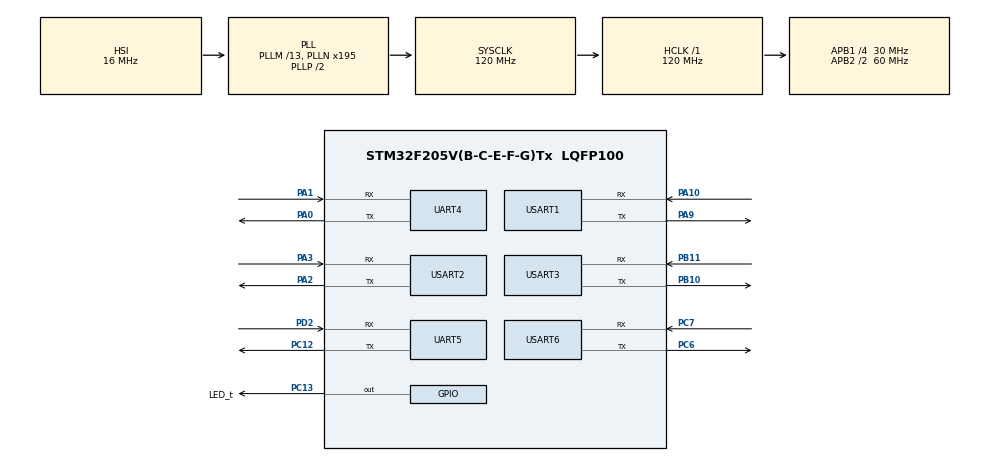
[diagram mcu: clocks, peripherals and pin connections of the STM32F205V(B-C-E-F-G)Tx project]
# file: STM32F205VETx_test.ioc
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FREERTOS.Tasks01=defaultTask,0,128,StartDefaultTask,Default,NULL,Dynamic,NULL,NULL;UartTask,-3,128,StartUartTask,Default,NULL,Static,UartTaskBuffer,UartTaskControlBlock
Mcu.Family=STM32F2
Mcu.Name=STM32F205V(B-C-E-F-G)Tx
Mcu.Package=LQFP100
NVIC.PriorityGroup=NVIC_PRIORITYGROUP_4
NVIC.TIM1_UP_TIM10_IRQn=true\:0\:0\:false\:false\:true\:false\:false\:true
NVIC.TimeBase=TIM1_UP_TIM10_IRQn
NVIC.TimeBaseIP=TIM1
PA0-WKUP.Mode=Asynchronous
PA0-WKUP.Signal=UART4_TX
PA1.Mode=Asynchronous
PA1.Signal=UART4_RX
PA10.Mode=Asynchronous
PA10.Signal=USART1_RX
PA2.Mode=Asynchronous
PA2.Signal=USART2_TX
PA3.Mode=Asynchronous
PA3.Signal=USART2_RX
PA9.Mode=Asynchronous
PA9.Signal=USART1_TX
PB10.Mode=Asynchronous
PB10.Signal=USART3_TX
PB11.Mode=Asynchronous
PB11.Signal=USART3_RX
PC12.Mode=Asynchronous
PC12.Signal=UART5_TX
PC13.GPIO_Label=LED_t
PC13.GPIO_ModeDefaultOutputPP=GPIO_MODE_OUTPUT_PP
PC13.GPIO_PuPd=GPIO_PULLUP
PC13.Signal=GPIO_Output
PC6.Mode=Asynchronous
PC6.Signal=USART6_TX
PC7.Mode=Asynchronous
PC7.Signal=USART6_RX
PD2.Mode=Asynchronous
PD2.Signal=UART5_RX
PH0-OSC_IN.Mode=HSE-External-Oscillator
PH0-OSC_IN.Signal=RCC_OSC_IN
PH1-OSC_OUT.Mode=HSE-External-Oscillator
PH1-OSC_OUT.Signal=RCC_OSC_OUT
ProjectManager.HeapSize=0x200
ProjectManager.StackSize=0x400
ProjectManager.TargetToolchain=MDK-ARM V5.27
RCC.48MHZClocksFreq_Value=60000000
RCC.AHBFreq_Value=120000000
RCC.APB1CLKDivider=RCC_HCLK_DIV4
RCC.APB1Freq_Value=30000000
RCC.APB1TimFreq_Value=60000000
RCC.APB2CLKDivider=RCC_HCLK_DIV2
RCC.APB2Freq_Value=60000000
RCC.APB2TimFreq_Value=120000000
RCC.CortexFreq_Value=120000000
RCC.HCLKFreq_Value=120000000
RCC.HSE_VALUE=8000000
RCC.HSI_VALUE=16000000
RCC.LSE_VALUE=32768
RCC.PLLM=13
RCC.PLLN=195
RCC.SYSCLKFreq_VALUE=120000000
RCC.SYSCLKSource=RCC_SYSCLKSOURCE_PLLCLK
RCC.VCOOutputFreq_Value=240000000
UART4.VirtualMode=Asynchronous
UART5.VirtualMode=Asynchronous
USART1.VirtualMode=VM_ASYNC
USART2.VirtualMode=VM_ASYNC
USART3.VirtualMode=VM_ASYNC
USART6.VirtualMode=VM_ASYNC
VP_FREERTOS_VS_CMSIS_V1.Mode=CMSIS_V1
VP_SYS_VS_tim1.Mode=TIM1
board=custom

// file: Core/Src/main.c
/* USER CODE BEGIN Header */
/**
  ******************************************************************************
  * @file           : main.c
  * @brief          : Main program body
  ******************************************************************************
  * @attention
  *
  * <h2><center>&copy; Copyright (c) 2022 STMicroelectronics.
  * All rights reserved.</center></h2>
  *
  * This software component is licensed by ST under Ultimate Liberty license
  * SLA0044, the "License"; You may not use this file except in compliance with
  * the License. You may obtain a copy of the License at:
  *                             www.st.com/SLA0044
  *
  ******************************************************************************
  */
/* USER CODE END Header */
#include "main.h"
#include "cmsis_os.h"
#include "usart.h"
#include "gpio.h"

void SystemClock_Config(void);
void MX_FREERTOS_Init(void);

/* USER CODE BEGIN 0 */
void vTaskCode( void * pvParameters )
 {
	 for( ;; )
	 {
		 // Task code goes here.
	 }
 }
/* USER CODE END 0 */

int main(void)
{

  /* MCU Configuration--------------------------------------------------------*/

  /* Reset of all peripherals, Initializes the Flash interface and the Systick. */
  HAL_Init();

  /* Configure the system clock */
  SystemClock_Config();

  /* Initialize all configured peripherals */
  MX_GPIO_Init();
  MX_USART1_UART_Init();
  MX_UART4_Init();
  MX_UART5_Init();
  MX_USART2_UART_Init();
  MX_USART3_UART_Init();
  MX_USART6_UART_Init();

  /* Call init function for freertos objects (in freertos.c) */
  MX_FREERTOS_Init();
  /* Start scheduler */
  osKernelStart();

  /* We should never get here as control is now taken by the scheduler */
  /* Infinite loop */
    while (1)
    {

    }
}

void SystemClock_Config(void)
{
  RCC_OscInitTypeDef RCC_OscInitStruct = {0};
  RCC_ClkInitTypeDef RCC_ClkInitStruct = {0};

  /** Initializes the RCC Oscillators according to the specified parameters
  * in the RCC_OscInitTypeDef structure.
  */
  RCC_OscInitStruct.OscillatorType = RCC_OSCILLATORTYPE_HSI;
  RCC_OscInitStruct.HSIState = RCC_HSI_ON;
  RCC_OscInitStruct.HSICalibrationValue = RCC_HSICALIBRATION_DEFAULT;
  RCC_OscInitStruct.PLL.PLLState = RCC_PLL_ON;
  RCC_OscInitStruct.PLL.PLLSource = RCC_PLLSOURCE_HSI;
  RCC_OscInitStruct.PLL.PLLM = 13;
  RCC_OscInitStruct.PLL.PLLN = 195;
  RCC_OscInitStruct.PLL.PLLP = RCC_PLLP_DIV2;
  RCC_OscInitStruct.PLL.PLLQ = 4;
  if (HAL_RCC_OscConfig(&RCC_OscInitStruct) != HAL_OK)
  {
    Error_Handler();
  }
  /** Initializes the CPU, AHB and APB buses clocks
  */
  RCC_ClkInitStruct.ClockType = RCC_CLOCKTYPE_HCLK|RCC_CLOCKTYPE_SYSCLK
                              |RCC_CLOCKTYPE_PCLK1|RCC_CLOCKTYPE_PCLK2;
  RCC_ClkInitStruct.SYSCLKSource = RCC_SYSCLKSOURCE_PLLCLK;
  RCC_ClkInitStruct.AHBCLKDivider = RCC_SYSCLK_DIV1;
  RCC_ClkInitStruct.APB1CLKDivider = RCC_HCLK_DIV4;
  RCC_ClkInitStruct.APB2CLKDivider = RCC_HCLK_DIV2;

  if (HAL_RCC_ClockConfig(&RCC_ClkInitStruct, FLASH_LATENCY_3) != HAL_OK)
  {
    Error_Handler();
  }
}

 /**
  * @brief  Period elapsed callback in non blocking mode
  * @note   This function is called  when TIM1 interrupt took place, inside
  * HAL_TIM_IRQHandler(). It makes a direct call to HAL_IncTick() to increment
  * a global variable "uwTick" used as application time base.
  * @param  htim : TIM handle
  * @retval None
  */
void HAL_TIM_PeriodElapsedCallback(TIM_HandleTypeDef *htim)
{
  if (htim->Instance == TIM1) {
    HAL_IncTick();
  }
}

void Error_Handler(void)
{
    __disable_irq();
    while (1)
    {
    }
}

/************************ (C) COPYRIGHT STMicroelectronics *****END OF FILE****/

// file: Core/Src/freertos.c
/* USER CODE BEGIN Header */
/**
  ******************************************************************************
  * File Name          : freertos.c
  * Description        : Code for freertos applications
  ******************************************************************************
  * @attention
  *
  * <h2><center>&copy; Copyright (c) 2022 STMicroelectronics.
  * All rights reserved.</center></h2>
  *
  * This software component is licensed by ST under Ultimate Liberty license
  * SLA0044, the "License"; You may not use this file except in compliance with
  * the License. You may obtain a copy of the License at:
  *                             www.st.com/SLA0044
  *
  ******************************************************************************
  */
/* USER CODE END Header */

#include "FreeRTOS.h"
#include "task.h"
#include "main.h"
#include "cmsis_os.h"

/* USER CODE BEGIN Includes */
#include "SDCard.h"
/* USER CODE END Includes */

osThreadId defaultTaskHandle;
osThreadId UartTaskHandle;
uint32_t UartTaskBuffer[ 128 ];
osStaticThreadDef_t UartTaskControlBlock;

void StartDefaultTask(void const * argument);
void StartUartTask(void const * argument);

void MX_FREERTOS_Init(void); /* (MISRA C 2004 rule 8.1) */

/* GetIdleTaskMemory prototype (linked to static allocation support) */
void vApplicationGetIdleTaskMemory( StaticTask_t **ppxIdleTaskTCBBuffer, StackType_t **ppxIdleTaskStackBuffer, uint32_t *pulIdleTaskStackSize );

/* USER CODE BEGIN GET_IDLE_TASK_MEMORY */
static StaticTask_t xIdleTaskTCBBuffer;
static StackType_t xIdleStack[configMINIMAL_STACK_SIZE];

void vApplicationGetIdleTaskMemory( StaticTask_t **ppxIdleTaskTCBBuffer, StackType_t **ppxIdleTaskStackBuffer, uint32_t *pulIdleTaskStackSize )
{
    *ppxIdleTaskTCBBuffer = &xIdleTaskTCBBuffer;
    *ppxIdleTaskStackBuffer = &xIdleStack[0];
    *pulIdleTaskStackSize = configMINIMAL_STACK_SIZE;
    /* place for user code */
}
/* USER CODE END GET_IDLE_TASK_MEMORY */

void MX_FREERTOS_Init(void) {

  /* Create the thread(s) */
  /* definition and creation of defaultTask */
  osThreadDef(defaultTask, StartDefaultTask, osPriorityNormal, 0, 128);
  defaultTaskHandle = osThreadCreate(osThread(defaultTask), NULL);

  /* definition and creation of UartTask */
  osThreadStaticDef(UartTask, StartUartTask, osPriorityIdle, 0, 128, UartTaskBuffer, &UartTaskControlBlock);
  UartTaskHandle = osThreadCreate(osThread(UartTask), NULL);

}

void StartDefaultTask(void const * argument)
{
  /* USER CODE BEGIN StartDefaultTask */
    /* Infinite loop */
    for(;;)
    {
			HAL_GPIO_WritePin(LED_t_GPIO_Port, LED_t_Pin, GPIO_PIN_RESET);
			osDelay(100);
			HAL_GPIO_WritePin(LED_t_GPIO_Port, LED_t_Pin, GPIO_PIN_SET);

        osDelay(100);
    }
  /* USER CODE END StartDefaultTask */
}

void StartUartTask(void const * argument)
{
  /* USER CODE BEGIN StartUartTask */
	//SD_Init();
  /* Infinite loop */
  for(;;)
  {

		EMLOG(LOG_INFO,"UartTask");

    osDelay(1000);
  }
  /* USER CODE END StartUartTask */
}

/************************ (C) COPYRIGHT STMicroelectronics *****END OF FILE****/
